# IOMUX_1.0 register map
Vendor: Texas Instruments
Peripheral module from a debugger description file (folder mspm0l211x_l112x).
Registers are 32-bit, access per field, no defined reset value unless marked. A register's access mark holds for its fields unless they carry their own. Offsets are as the file gives them; lines under a group give offsets from that group; [hi:lo] are bit positions; {n}, {i} and the like mark numbered series; 'fields as' and 'values as' point back to an identical list; <NAME> marks a mode.

## IOMUX
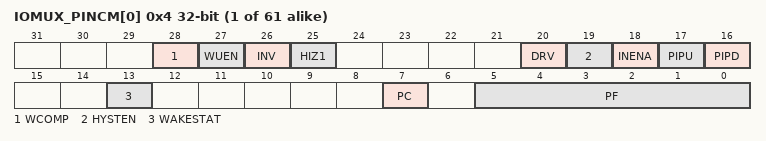
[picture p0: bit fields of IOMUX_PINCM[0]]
{0x4+4i} IOMUX_PINCM[{i}] (i=0..60) — Pin Control Management Register in SECCFG region
  [28] WCOMP rw — Wakeup Compare Value bit
    0=MATCH0 (Wakeup on a match of 0); 1=MATCH1 (Wakeup on a match of 1)
  [27] WUEN rw — Wakeup Enable bit
    0=DISABLE (wakeup is disabled.); 1=ENABLE (wakeup is enabled)
  [26] INV rw — Data inversion selection
    0=DISABLE (Data inversion is disabled.); 1=ENABLE (Data inversion is enabled)
  [25] HIZ1 rw — High output value will tri-state the output when this bit is enabled
    0=DISABLE (open-drain is disabled.); 1=ENABLE (open-drain is enabled.)
  [20] DRV rw — Drive strength control selection, for HS IOCELL only
    0=DRVVAL0 (Drive setting of 0 selected); 1=DRVVAL1 (Drive setting of 1 selected)
  [19] HYSTEN rw — Hysteresis Enable Control Selection
    0=DISABLE (hysteresis is disabled.); 1=ENABLE (hysteresis is enabled)
  [18] INENA rw — Input Enable Control Selection
    0=DISABLE (Input enable is disabled.); 1=ENABLE (Input enable is enabled.)
  [17] PIPU rw — Pull Up control selection
    0=DISABLE (Pull up is disabled.); 1=ENABLE (Pull up is enabled)
  [16] PIPD rw — Pull Down control selection
    0=DISABLE (Pull down is disabled.); 1=ENABLE (Pull down is enabled)
  [13] WAKESTAT ro — This has the IOPAD WAKEUP signal as status bit.
    0=DISABLE (wakeup source is NOT from this IOCELL); 1=ENABLE (wakeup source is from this IOCELL)
  [7] PC rw — Peripheral is Connected
    0=UNCONNECTED (The output of the peripheral (and its output enable) will not propagate to the IOCELL); 1=CONNECTED (The output latch of the dataflow will be transparent)
  [5:0] PF rw — Peripheral Function selection bits
    0=MINIMUM (Reserved as unconnected); 63=MAXIMUM (An encoding per function that can be connected to this pin.)
